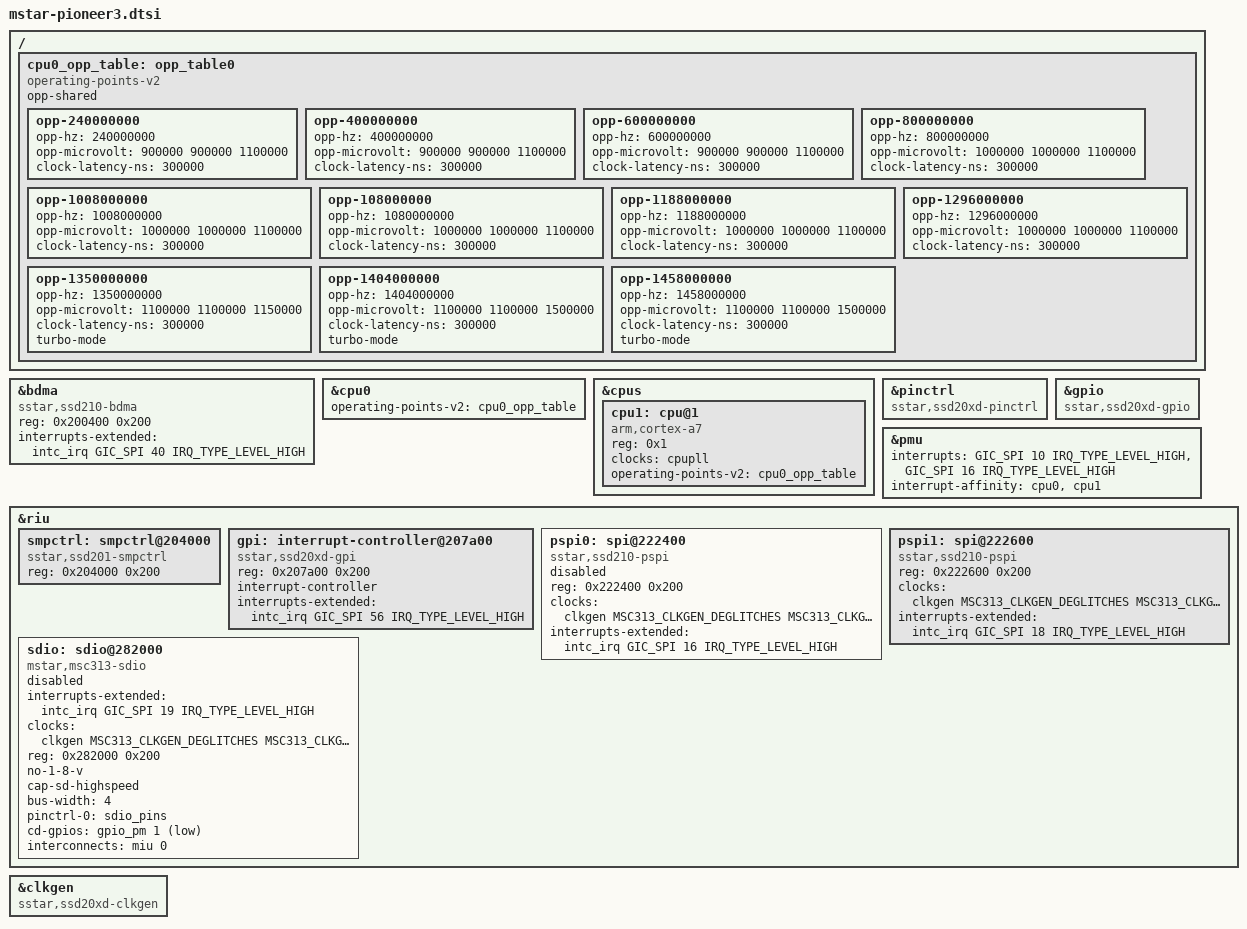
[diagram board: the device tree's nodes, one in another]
// SPDX-License-Identifier: GPL-2.0-or-later
/*
 * Copyright (c) 2020 thingy.jp.
 * Author: Daniel Palmer <daniel@thingy.jp>
 */

#include "mstar-v7.dtsi"

#include <dt-bindings/gpio/gpio.h>

/ {
	cpu0_opp_table: opp_table0 {
		compatible = "operating-points-v2";
		opp-shared;

		opp-240000000 {
			opp-hz = /bits/ 64 <240000000>;
			opp-microvolt = <900000 900000 1100000>;
			clock-latency-ns = <300000>;
		};

		opp-400000000 {
			opp-hz = /bits/ 64 <400000000>;
			opp-microvolt = <900000 900000 1100000>;
			clock-latency-ns = <300000>;
		};

		opp-600000000 {
			opp-hz = /bits/ 64 <600000000>;
			opp-microvolt = <900000 900000 1100000>;
			clock-latency-ns = <300000>;
		};

		opp-800000000 {
			opp-hz = /bits/ 64 <800000000>;
			opp-microvolt = <1000000 1000000 1100000>;
			clock-latency-ns = <300000>;
		};

		opp-1008000000 {
			opp-hz = /bits/ 64 <1008000000>;
			opp-microvolt = <1000000 1000000 1100000>;
			clock-latency-ns = <300000>;
		};

		opp-108000000 {
			opp-hz = /bits/ 64 <1080000000>;
			opp-microvolt = <1000000 1000000 1100000>;
			clock-latency-ns = <300000>;
		};

		opp-1188000000 {
			opp-hz = /bits/ 64 <1188000000>;
			opp-microvolt = <1000000 1000000 1100000>;
			clock-latency-ns = <300000>;
		};

		opp-1296000000 {
			opp-hz = /bits/ 64 <1296000000>;
			opp-microvolt = <1000000 1000000 1100000>;
			clock-latency-ns = <300000>;
		};

		/* Overclock. Stable upto 1.8GHz */
		opp-1350000000 {
			opp-hz = /bits/ 64 <1350000000>;
			opp-microvolt = <1100000 1100000 1150000>;
			clock-latency-ns = <300000>;
			turbo-mode;
		};

		opp-1404000000 {
			opp-hz = /bits/ 64 <1404000000>;
			opp-microvolt = <1100000 1100000 1500000>;
			clock-latency-ns = <300000>;
			turbo-mode;
		};

		opp-1458000000 {
			opp-hz = /bits/ 64 <1458000000>;
			opp-microvolt = <1100000 1100000 1500000>;
			clock-latency-ns = <300000>;
			turbo-mode;
		};

#if 0
		opp-1512000000 {
			opp-hz = /bits/ 64 <1512000000>;
			opp-microvolt = <1000000 1000000 1100000>;
			clock-latency-ns = <300000>;
			turbo-mode;
		};

		opp-1600000000 {
			opp-hz = /bits/ 64 <1600000000>;
			opp-microvolt = <1000000 1000000 1100000>;
			clock-latency-ns = <300000>;
			turbo-mode;
		};

		opp-1700000000 {
			opp-hz = /bits/ 64 <1700000000>;
			opp-microvolt = <1000000 1000000 1100000>;
			clock-latency-ns = <300000>;
			turbo-mode;
		};

		opp-1800000000 {
			opp-hz = /bits/ 64 <1800000000>;
			opp-microvolt = <1000000 1000000 1100000>;
			clock-latency-ns = <300000>;
			turbo-mode;
		};
#endif
	};
};

&bdma {
	compatible = "sstar,ssd210-bdma";
	reg = <0x200400 0x200>;
	interrupts-extended = <&intc_irq GIC_SPI 40 IRQ_TYPE_LEVEL_HIGH>;
};

&cpu0 {
	operating-points-v2 = <&cpu0_opp_table>;
};

&cpus {
	cpu1: cpu@1 {
		device_type = "cpu";
		compatible = "arm,cortex-a7";
		reg = <0x1>;
		clocks = <&cpupll>;
		clock-names = "cpuclk";
		operating-points-v2 = <&cpu0_opp_table>;
	};
};

&pinctrl {
	compatible = "sstar,ssd20xd-pinctrl";
};

&gpio {
	compatible = "sstar,ssd20xd-gpio";
	/delete-property/ gpio-ranges;
	status = "okay";
};

&pmu {
	interrupts = <GIC_SPI 10 IRQ_TYPE_LEVEL_HIGH>,
		     <GIC_SPI 16 IRQ_TYPE_LEVEL_HIGH>;
	interrupt-affinity = <&cpu0>, <&cpu1>;
};

&riu {
	smpctrl: smpctrl@204000 {
		compatible = "sstar,ssd201-smpctrl", "mstar,smpctrl";
		reg = <0x204000 0x200>;
	};

	gpi: interrupt-controller@207a00 {
		compatible = "sstar,ssd20xd-gpi";
		reg = <0x207a00 0x200>;
		#interrupt-cells = <2>;
		interrupt-controller;
		interrupts-extended = <&intc_irq GIC_SPI 56 IRQ_TYPE_LEVEL_HIGH>;
	};

	pspi0: spi@222400 {
		compatible = "sstar,ssd210-pspi";
		reg = <0x222400 0x200>;
		clocks = <&clkgen MSC313_CLKGEN_DEGLITCHES MSC313_CLKGEN_PSPI0 0>;
		interrupts-extended = <&intc_irq GIC_SPI 16 IRQ_TYPE_LEVEL_HIGH>;
		status = "disabled";
	};

	pspi1: spi@222600 {
		compatible = "sstar,ssd210-pspi";
		reg = <0x222600 0x200>;
		clocks = <&clkgen MSC313_CLKGEN_DEGLITCHES MSC313_CLKGEN_PSPI1 0>;
		interrupts-extended = <&intc_irq GIC_SPI 18 IRQ_TYPE_LEVEL_HIGH>;
		//status = "disabled";
	};

	sdio: sdio@282000 {
		compatible = "mstar,msc313-sdio";
		interrupts-extended = <&intc_irq GIC_SPI 19 IRQ_TYPE_LEVEL_HIGH>;
		clocks = <&clkgen MSC313_CLKGEN_DEGLITCHES MSC313_CLKGEN_SDIO 0>;
		reg = <0x282000 0x200>;
		no-1-8-v;
		cap-sd-highspeed;
		bus-width = <4>;
		pinctrl-names = "default";
		pinctrl-0 = <&sdio_pins>;
		//broken-cd;
		cd-gpios = <&gpio_pm 1 GPIO_ACTIVE_LOW>;
		interconnects = <&miu 0>;
		interconnect-names = "dma-mem";
		status = "disabled";
	};
};

&clkgen {
	compatible = "sstar,ssd20xd-clkgen";
};
